# NANO100BN_v1 register map
File version: 1.0
Registers are 32-bit, read-write, reset 0x0 unless marked. A register's access mark holds for its fields unless they carry their own. Offsets are from the block's base; [hi:lo] are bit positions; {n}, {i} and the like mark numbered series.

## USB — USB Register Map
Base 0x40060000
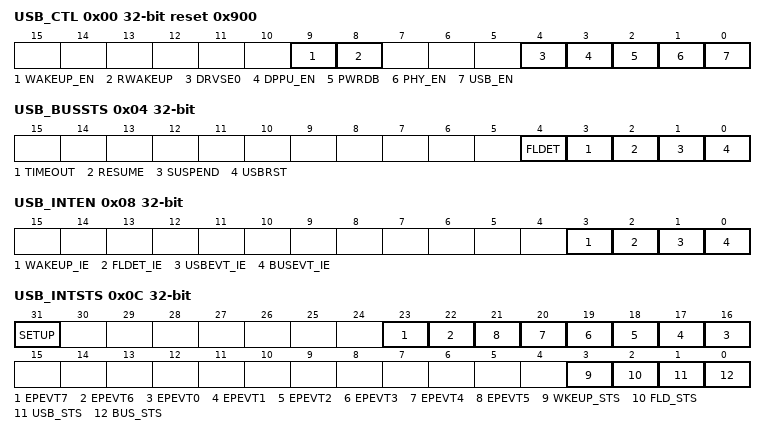
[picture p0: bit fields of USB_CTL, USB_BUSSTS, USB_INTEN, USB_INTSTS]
0x00 USB_CTL reset 0x900 — USB Control Register
  [9] WAKEUP_EN — Wake-Up Function Enable
    0=USB wake-up function Disabled; 1=USB wake-up function Enabled
  [8] RWAKEUP — Remote Wake-up
    0=Don't force USB bus to K state; 1=Force USB bus to K (USB_DP low, USB_DM: high) state, used for remote wake-up
  [4] DRVSE0 — Force USB PHY Transceiver to Drive SE0 (Single Ended Zero). The Single Ended Zero is present when both lines (USB_DP, USB_DM) are being pulled low. The default value is "1".
    0=None; 1=Force USB PHY transceiver to drive SE0
  [3] DPPU_EN — Pull-Up Resistor on USB_DP Enable
    0=Pull-up resistor in USB_DP bus Disabled; 1=Pull-up resistor in USB_DP bus will be active
  [2] PWRDB — Power down PHY Transceiver, Low Active
    0=Power-down related circuit of PHY transceiver; 1=Turn-on related circuit of PHY transceiver
  [1] PHY_EN — PHY Transceiver Enable
    0=PHY transceiver Disabled; 1=PHY transceiver Enabled
  [0] USB_EN — USB Function Enable
    0=USB Disabled; 1=USB Enabled
0x04 USB_BUSSTS ro — USB Bus Status Register
  [4] FLDET — Device Floating Detection
    0=The controller didn't attach into the USB; 1=When the controller is attached into the USB, this bit will be set as "1"
  [3] TIMEOUT — Time-out Flag
    1=Bus no any response more than 18 bits time. It is read only
  [2] RESUME — Resume Status
    1=Resume from suspend. It is read only
  [1] SUSPEND — Suspend Status
    1=Bus idle more than 3 ms, either cable is plugged off or host is sleeping. It is read only
  [0] USBRST — USB Reset Status
    1=Bus reset when SE0 (single-ended 0) more than 2.5uS. It is read only
0x08 USB_INTEN — Interrupt Enable Register
  [3] WAKEUP_IE — USB Wake-up Interrupt Enable
    0=Wake-up Interrupt Disabled; 1=Wake-up Interrupt Enabled
  [2] FLDET_IE — Floating Detect Interrupt Enable
    0=Floating detect Interrupt Disabled; 1=Floating detect Interrupt Enabled
  [1] USBEVT_IE — USB Event Interrupt Enable
    0=USB event interrupt Disabled; 1=USB event interrupt Enabled
  [0] BUSEVT_IE — Bus Event Interrupt Enable
    0=BUS event interrupt Disabled; 1=BUS event interrupt Enabled
0x0C USB_INTSTS — Interrupt Event Status Register
  [31] SETUP — Setup Event Status
    0=No Setup event; 1=Setup event occurred, cleared by write "1" to USB_INTSTS[31]
  [23] EPEVT7 — USB Event Status on EP7
    0=No event occurred in Endpoint 7; 1=USB event occurred on Endpoint 7, check USB_EPSTS2[6:4] to know which kind of USB event was occurred, cleared by write "1" to USB_INTSTS [23] or USB_INTSTS [1]
  [22] EPEVT6 — USB Event Status on EP6
    0=No event occurred in Endpoint 6; 1=USB event occurred on Endpoint 6, check USB_EPSTS2[2:0] to know which kind of USB event was occurred, cleared by write "1" to USB_INTSTS [22] or USB_INTSTS [1]
  [n+16] EPEVT{n} (n=0..5) — USB Event Status on EP{n}
    0=No event occurred in Endpoint {n}; 1=USB event occurred on Endpoint {n}, check USB_EPSTS[{4n+11}:{4n+8}] to know which kind of USB event was occurred, cleared by write "1" to USB_INTSTS [{n+16}] or USB_INTSTS [1]
  [3] WKEUP_STS — Wake-up Interrupt Status
    0=No wake-up event is occurred; 1=Wake-up event occurred, cleared by write 1 to USB_INTSTS [3]
  [2] FLD_STS — Floating Interrupt Status
    0=There is not attached event in the USB; 1=There is attached event in the USB and it is cleared by write "1" to USB_INTSTS [2]
  [1] USB_STS — USB Interrupt Status. The USB event means that there is Setup Token, IN token, OUT ACK, ISO IN, or ISO OUT event in the bus. This bit is used to indicate that there is one of events in the bus.
    0=No USB event is occurred; 1=USB event occurred, check EPSTS0~7[3:0] in USB_EPSTS [31:8] to know which kind of USB event was occurred, cleared by write "1" to USB_INTSTS [1] or USB_INTSTS[31] or EPEVT0~7
  [0] BUS_STS — BUS Interrupt Status. The BUS event means there is bus suspense or bus resume in the bus. This bit is used to indicate that there is one of events in the bus.
    0=No BUS event is occurred; 1=BUS event occurred; check USB_BUSSTS [3:0] to know which kind of bus event was occurred, cleared by write "1" to USB_INTSTS [0]
0x10 USB_FADDR — Device 's Function Address Register
  [6:0] FADDR — USB device's function address
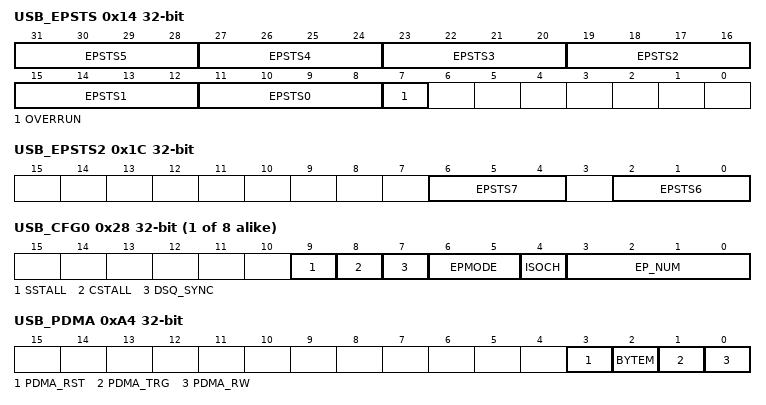
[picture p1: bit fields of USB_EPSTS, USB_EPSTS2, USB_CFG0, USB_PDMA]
0x14 USB_EPSTS ro — Endpoint Status Register
  [4n+11:4n+8] EPSTS{n} (n=0..5) — Endpoint {n} Bus Status
  [7] OVERRUN — Overrun. It means the received data is over the maximum payload number or not.
    0=No overrun; 1=Out Data more than the Max Payload in MXPLD register or the Setup Data more than 8 Bytes
0x18 USB_BUFSEG — Setup Token Buffer Segmentation Register
  [8:3] BUFSEG
0x1C USB_EPSTS2 ro — Endpoint Bus Status
  [6:4] EPSTS7 — Endpoint 7 Bus Status
  [2:0] EPSTS6 — Endpoint 6 Bus Status
{0x20+0x10*i} USB_BUFSEG{i} (i=0..7) — Endpoint {i} Buffer Segmentation Register
  [8:3] BUFSEG — Refer to the section 5.4.3.3 for the endpoint SRAM structure and its description.
{0x24+0x10*i} USB_MXPLD{i} (i=0..7) — Endpoint {i} Maximal Payload Register
  [8:0] MXPLD — Maximal Payload. It is used to define the length of data which is transmitted to host (IN token) or the actual length of data receiving from host (OUT token). It also used to indicate that the endpoint is ready to be transmitted in IN token or received in OUT token. (1). When the register is written by CPU, For IN token, the value of MXPLD is used to define the length of data to be transmitted and indicate the data buffer is ready. For OUT token, it means that the controller is ready to receive data from host and the value of MXPLD is the maximal data length comes from host. (2). When the register is read by CPU, For IN token, the value of MXPLD is indicated the length of data be transmitted to host. For OUT token, the value of MXPLD is indicated the actual length of data receiving from host. Note: Once MXPLD is written, the data packets will be transmitted/received immediately after IN/OUT token arrived.
{0x28+0x10*i} USB_CFG{i} (i=0..7) — Endpoint {i} Configuration Register
  [9] SSTALL — Set STALL Response
    0=Disable the device to response STALL; 1=Set the device to respond STALL automatically
  [8] CSTALL — Clear STALL Response
    0=Disable the device to clear the STALL handshake in setup stage; 1=Clear the device to response STALL handshake in setup stage
  [7] DSQ_SYNC — Data Sequence Synchronization. It is used to specify the DATA0 or DATA1 PID in the current transaction. It will toggle automatically in IN token after host response ACK. In the other tokens, the user shall take care of it to confirm the right PID in its transaction.
    0=DATA0 PID; 1=DATA1 PID
  [6:5] EPMODE — Endpoint Mode
  [4] ISOCH — Isochronous Endpoint. This bit is used to set the endpoint as Isochronous endpoint, no handshake.
  [3:0] EP_NUM — Endpoint Number. These bits are used to define the endpoint number of the current endpoint
0xA0 USB_BIST — USB Buffer Self Test Control Register
0xA4 USB_PDMA — USB PDMA Control Register
  [3] PDMA_RST — PDMA Reset. It is used to reset the USB PDMA function into default state. Note: it is auto cleared to 0 after the reset function done.
    0=No Reset PDMA Reset Disable; 1=Reset the PDMA function in this controller
  [2] BYTEM — CPU access USB SRAM Size Mode Select
    0=Word Mode: The size of the transfer from CPU to USB SRAM is Word order; 1=Byte Mode: The size of the transfer from CPU to USB SRAM is Byte order
  [1] PDMA_TRG — Active PDMA Function. This bit will be automatically cleared after PDMA transfer done.
    0=The PDMA function is not active; 1=The PDMA function in USB is active
  [0] PDMA_RW
    0=The PDMA will read data from memory to USB buffer; 1=The PDMA will read data from USB buffer to memory
